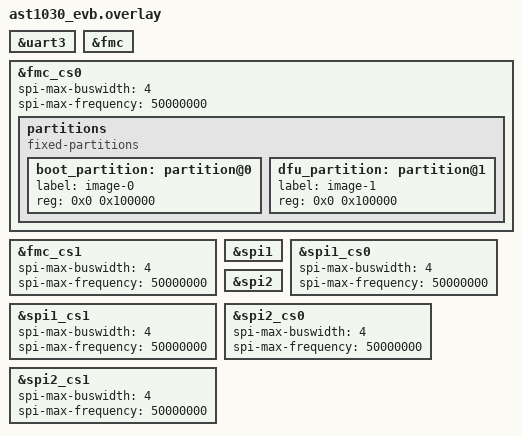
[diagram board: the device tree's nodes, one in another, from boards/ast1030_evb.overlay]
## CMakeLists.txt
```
# SPDX-License-Identifier: Apache-2.0

cmake_minimum_required(VERSION 3.13.1)

find_package(Zephyr HINTS $ENV{ZEPHYR_BASE})
project(ast1030_evb_uart_bin_xfer_sample)

FILE(GLOB app_sources src/*.c)
target_sources(app PRIVATE ${app_sources})
```

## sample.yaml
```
sample:
  name: Aspeed uart bin-xfer function demo sample
tests:
  sample.board.ast1030_evb:
    platform_allow: ast1030_evb
```

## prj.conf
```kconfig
CONFIG_SPI=y
CONFIG_THREAD_RUNTIME_STATS=y
CONFIG_FLASH=y
CONFIG_SPI_NOR_MULTI_DEV=y
CONFIG_FLASH_SHELL=y
CONFIG_HEAP_MEM_POOL_SIZE=16384
CONFIG_MINIMAL_LIBC_MALLOC_ARENA_SIZE=16384
CONFIG_REBOOT=y
CONFIG_POSIX_CLOCK=y
CONFIG_STACK_SENTINEL=y
CONFIG_LOG=y
CONFIG_SHELL=y
CONFIG_SHELL_BACKEND_SERIAL_INIT_PRIORITY=99
CONFIG_SHELL_STACK_SIZE=4096
```

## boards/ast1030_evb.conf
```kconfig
CONFIG_SPI_ASPEED=y
CONFIG_UART_ASPEED=y
CONFIG_FLASH=y
CONFIG_FLASH_PAGE_LAYOUT=y
CONFIG_IMG_BLOCK_BUF_SIZE=4096
CONFIG_SHELL_ARGC_MAX=70
```

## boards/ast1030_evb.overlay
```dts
&uart3{
	status = "okay";
};

&fmc {
	status = "okay";
};

&fmc_cs0 {
	status = "okay";
	spi-max-buswidth = <4>;
	spi-max-frequency = <50000000>;

	partitions {
		compatible = "fixed-partitions";
		#address-cells = <1>;
		#size-cells = <1>;
		boot_partition: partition@0 {
			label = "image-0";
			reg = <0x0 0x100000>;
		};
		dfu_partition: partition@1 {
		       label = "image-1";
		       reg = <0x0 0x100000>;
	       };
	};
};

&fmc_cs1 {
	status = "okay";
	spi-max-buswidth = <4>;
	spi-max-frequency = <50000000>;
};

&spi1 {
	status = "okay";
};

&spi1_cs0 {
	status = "okay";
	spi-max-buswidth = <4>;
	spi-max-frequency = <50000000>;
};

&spi1_cs1 {
	status = "okay";
	spi-max-buswidth = <4>;
	spi-max-frequency = <50000000>;
};

&spi2 {
	status = "okay";
};

&spi2_cs0 {
	status = "okay";
	spi-max-buswidth = <4>;
	spi-max-frequency = <50000000>;
};

&spi2_cs1 {
	status = "okay";
	spi-max-buswidth = <4>;
	spi-max-frequency = <50000000>;
};
```

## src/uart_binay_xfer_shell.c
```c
#include <stdio.h>
#include <stdlib.h>
#include <string.h>
#include <device.h>
#include <shell/shell.h>
#include <drivers/uart.h>
#include <drivers/flash.h>


static const struct uart_config uart_config = {
	.baudrate = 115200,
	.parity = UART_CFG_PARITY_NONE,
	.stop_bits = UART_CFG_STOP_BITS_1,
	.data_bits = UART_CFG_DATA_BITS_8,
	.flow_ctrl = UART_CFG_FLOW_CTRL_NONE,
};

static int cmd_bin_xfer(const struct shell *shell, size_t argc, char **argv)
{
	const struct device *uart_dev, *flash_dev;
	uint32_t flash_offset, binary_size, xfer_size;
	unsigned char *binary_buffer;
	int i;

	uart_dev = device_get_binding(argv[1]);
	if (!uart_dev) {
		shell_error(shell, "UART device not found");
		return -EINVAL;
	}
	flash_dev = device_get_binding(argv[2]);
	if (!flash_dev) {
		shell_error(shell, "flash device not found");
		return -EINVAL;
	}
	uart_configure(uart_dev, &uart_config);

	flash_offset = strtoul(argv[3], NULL, 16);
	binary_buffer = malloc(4096);
	flash_read(flash_dev, flash_offset, binary_buffer, 4);
	binary_size = ((uint32_t *)binary_buffer)[0] + 4;

	shell_print(shell, "uart boot binary size = %x", binary_size);

	while (binary_size) {
		xfer_size = (binary_size >= 4096) ? 4096 : binary_size;

		flash_read(flash_dev, flash_offset, binary_buffer, xfer_size);
		for (i = 0; i < xfer_size; i++) {
			uart_poll_out(uart_dev, binary_buffer[i]);
		}
		binary_size -= xfer_size;
		flash_offset += xfer_size;
	}
	free(binary_buffer);

	return 0;
}

SHELL_STATIC_SUBCMD_SET_CREATE(
	uart_cmds,
	SHELL_CMD_ARG(bin_xfer, NULL, "<uart_device> <flash_device> <flash_offset(hex)>",
		      cmd_bin_xfer, 4, 0),
	SHELL_SUBCMD_SET_END);

SHELL_CMD_REGISTER(uart, &uart_cmds, "Uart bin-xfer commands", NULL);
```
